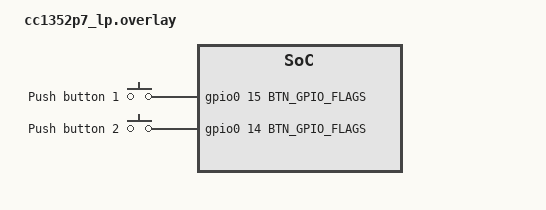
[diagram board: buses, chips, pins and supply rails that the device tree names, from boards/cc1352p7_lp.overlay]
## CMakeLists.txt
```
# SPDX-License-Identifier: Apache-2.0

cmake_minimum_required(VERSION 3.20.0)

find_package(Zephyr REQUIRED HINTS $ENV{ZEPHYR_BASE})
project(ot_button_joiner)

target_sources(app PRIVATE src/main.c)
```

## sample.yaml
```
common:
  harness: net
  tags:
    - net
  min_flash: 140
sample:
  description: OpenThread joiner and commissioner sample
  name: OpenThread Joiner
tests:
  sample.openthread.joiner:
    build_only: true
    platform_allow:
      - cc1352p7_lp
    extra_args: EXTRA_CONF_FILE=joiner.conf
  sample.openthread.commissioner:
    build_only: true
    platform_allow:
      - cc1352p7_lp
    extra_args: EXTRA_CONF_FILE=commissioner.conf
```

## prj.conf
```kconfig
# Kernel options
CONFIG_MAIN_STACK_SIZE=2560
CONFIG_INIT_STACKS=y

# Network options
CONFIG_NETWORKING=y
CONFIG_NET_L2_OPENTHREAD=y

# Increase logging thread stack size due to Spinel backend needs
CONFIG_LOG_PROCESS_THREAD_STACK_SIZE=2048

CONFIG_OPENTHREAD_DIAG=y
CONFIG_OPENTHREAD_DHCP6_CLIENT=y
CONFIG_OPENTHREAD_ENABLE_SERVICE=y

CONFIG_SHELL=y
CONFIG_OPENTHREAD_SHELL=y

CONFIG_MBEDTLS_HEAP_SIZE=15360

CONFIG_OPENTHREAD_SRP_CLIENT=y

CONFIG_OPENTHREAD_COAP=y
CONFIG_OPENTHREAD_SLAAC=y

CONFIG_LED=y

# Required for OpenThread Settings
CONFIG_NVS=y
CONFIG_SETTINGS_NVS=y

# Input
CONFIG_INPUT=y
CONFIG_INPUT_LONGPRESS=y

# Reboot
CONFIG_REBOOT=y

# FIXME
# This workaround the following issue with joiner:
# Join failed [Security]
CONFIG_OPENTHREAD_DEBUG=y
CONFIG_OPENTHREAD_LOG_LEVEL_INFO=y
```

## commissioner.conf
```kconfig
# Commissioner
CONFIG_OPENTHREAD_JOINER=n
CONFIG_OPENTHREAD_COMMISSIONER=y
```

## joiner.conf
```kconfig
# Openthread options
CONFIG_OPENTHREAD_JOINER=y
CONFIG_OPENTHREAD_COMMISSIONER=n
```

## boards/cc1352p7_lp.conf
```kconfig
CONFIG_LED_BLINK_FALLBACK=y
```

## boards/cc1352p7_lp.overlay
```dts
#include <zephyr/dt-bindings/input/input-event-codes.h>

/ {

	/* TODO: Add a node name to cc1352p7 */
	buttons: keys {
		compatible = "gpio-keys";
		btn0: btn_0 {
			gpios = <&gpio0 15 BTN_GPIO_FLAGS>;
			label = "Push button 1";
			zephyr,code = <INPUT_KEY_0>;
		};
		btn1: btn_1 {
			gpios = <&gpio0 14 BTN_GPIO_FLAGS>;
			label = "Push button 2";
			zephyr,code = <INPUT_KEY_1>;
		};
	};

	longpress {
		input = <&buttons>;
		compatible = "zephyr,input-longpress";
		input-codes = <INPUT_KEY_0>, <INPUT_KEY_1>;
		short-codes = <INPUT_KEY_A>, <INPUT_KEY_B>;
		long-codes = <INPUT_KEY_X>, <INPUT_KEY_Y>;
		long-delay-ms = <2000>;
	};
};
```

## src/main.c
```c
/*
 * Copyright (c) 2025 Alexandre Bailon
 *
 * SPDX-License-Identifier: Apache-2.0
 */

#include <stdio.h>
#include <zephyr/input/input.h>
#include <zephyr/drivers/led.h>
#include <zephyr/net/openthread.h>
#include <zephyr/version.h>

#include <openthread/thread.h>

#include <zephyr/sys/reboot.h>

#define OT_JOINER_PSKD "J01NME"
#if defined(CONFIG_OPENTHREAD_PLATFORM_INFO)
#define OT_PLATFORM_INFO CONFIG_OPENTHREAD_PLATFORM_INFO
#else
#define OT_PLATFORM_INFO ""
#endif
#define ZEPHYR_PACKAGE_NAME "Zephyr"
#define PACKAGE_VERSION     KERNEL_VERSION_STRING

static const struct device *leds = DEVICE_DT_GET_OR_NULL(DT_INST(0, gpio_leds));

#ifdef CONFIG_OPENTHREAD_COMMISSIONER

void ot_commissioner_state_changed(otCommissionerState aState, void *user_data)
{
	struct otInstance *ot_instance = openthread_get_default_instance();
	int ret;

	if (aState == OT_COMMISSIONER_STATE_ACTIVE) {
		ret = otCommissionerAddJoiner(ot_instance, NULL, OT_JOINER_PSKD, 120);
		if (ret != OT_ERROR_NONE) {
			printf("Failed to add a joiner: %d\n", ret);
			led_blink(leds, 0, 200, 200);
		} else {
			led_blink(leds, 0, 1000, 1000);
		}
	} else if (aState == OT_COMMISSIONER_STATE_PETITION) {
		led_blink(leds, 0, 500, 500);
	} else {
		led_off(leds, 0);
	}
}

void joinerCallback(otCommissionerJoinerEvent aEvent, const otJoinerInfo *aJoinerInfo,
		    const otExtAddress *aJoinerId, void *aContext)
{
	(void)aContext;
	struct otInstance *ot_instance = openthread_get_default_instance();

	switch (aEvent) {
	case OT_COMMISSIONER_JOINER_END:
	case OT_COMMISSIONER_JOINER_REMOVED:
		otCommissionerStop(ot_instance);
	default:
	}
}

static void ot_commissioner_work_handler(struct k_work *work)
{
	struct otInstance *ot_instance = openthread_get_default_instance();
	int ret;

	ret = otCommissionerStart(ot_instance, ot_commissioner_state_changed, joinerCallback, NULL);
	if (ret != OT_ERROR_NONE) {
		printf("Failed to start commissioner\n");
		led_blink(leds, 0, 200, 200);
	}
}

K_WORK_DEFINE(ot_commissioner_work, ot_commissioner_work_handler);

#endif

#ifdef CONFIG_OPENTHREAD_JOINER

K_MUTEX_DEFINE(joiner_mutex);
K_CONDVAR_DEFINE(joiner_condvar);

static void ot_joiner_start_handler(otError error, void *context)
{
	struct otInstance *ot_instance = openthread_get_default_instance();

	k_mutex_lock(&joiner_mutex, K_FOREVER);
	switch (error) {
	case OT_ERROR_NONE:
		printf("Join success\n");
		otThreadSetEnabled(ot_instance, true);
		break;
	default:
		printf("Join failed [%d]\n", error);
		if (error != OT_ERROR_NOT_FOUND) {
			led_blink(leds, 0, 500, 500);
		}
		k_condvar_signal(&joiner_condvar);
		break;
	}
	k_mutex_unlock(&joiner_mutex);
}

static void ot_joiner_thread(void *, void *, void *)
{
	struct openthread_context *ot_context = openthread_get_default_context();
	struct otInstance *ot_instance = openthread_get_default_instance();
	otError error = OT_ERROR_NONE;

	printf("Joining a Thread network!\n");
	error = otThreadSetEnabled(ot_instance, false);
	if (error != OT_ERROR_NONE) {
		printf("Failed to stop the OpenThread network [%d]\n", error);
	}

	printf("Set broadcast PANID\n");
	otLinkSetPanId(ot_instance, OT_PANID_BROADCAST);

	k_mutex_lock(&joiner_mutex, K_FOREVER);
	do {
		printf("Starting OpenThread join procedure.\n");
		error = otJoinerStart(ot_instance, OT_JOINER_PSKD, NULL, ZEPHYR_PACKAGE_NAME,
				      OT_PLATFORM_INFO, PACKAGE_VERSION, NULL,
				      &ot_joiner_start_handler, ot_context);
		if (error != OT_ERROR_NONE) {
			printf("Failed to start joiner [%d]\n", error);
			led_blink(leds, 0, 200, 200);
		} else {
			k_condvar_wait(&joiner_condvar, &joiner_mutex, K_FOREVER);
		}
	} while (!otDatasetIsCommissioned(ot_instance));
	printf("Done!\n");
	led_on(leds, 0);
	k_mutex_unlock(&joiner_mutex);
}

static void ot_state_changed(otChangedFlags flags, void *user_data)
{
	if (flags & OT_CHANGED_PENDING_DATASET) {
		k_mutex_lock(&joiner_mutex, K_FOREVER);
		k_condvar_signal(&joiner_condvar);
		k_mutex_unlock(&joiner_mutex);
	}
}

static struct openthread_state_changed_callback ot_state_changed_cb = {
	.otCallback = ot_state_changed,
};

#define JOINER_STACK_SIZE 2048
#define JOINER_PRIORITY   -1

K_THREAD_DEFINE(joiner_tid, JOINER_STACK_SIZE, ot_joiner_thread, NULL, NULL, NULL, JOINER_PRIORITY,
		0, -1);
#endif

static void button_pressed(struct input_event *event, void *user_data)
{
	if (!event->value) {
		return;
	}

	if (event->code == INPUT_KEY_X) {
#ifdef CONFIG_OPENTHREAD_JOINER
		struct otInstance *ot_instance = openthread_get_default_instance();

		printf("Factory Reset!\n");
		otInstanceFactoryReset(ot_instance);
#endif
#ifdef CONFIG_OPENTHREAD_COMMISSIONER
		k_work_submit(&ot_commissioner_work);
#endif
	}
}

INPUT_CALLBACK_DEFINE(NULL, button_pressed, NULL);

int main(void)
{
	if (!device_is_ready(leds)) {
		printf("Device %s is not ready", leds->name);
		return -ENODEV;
	}

#ifdef CONFIG_OPENTHREAD_JOINER
	struct otInstance *ot_instance = openthread_get_default_instance();

	if (!otDatasetIsCommissioned(ot_instance)) {
		led_blink(leds, 0, 1000, 1000);
		k_thread_start(joiner_tid);
	} else {
		led_on(leds, 0);
	}

	openthread_state_changed_callback_register(&ot_state_changed_cb);
#endif

	return 0;
}
```
